AUTOSAR XML (schema 4-2-2)
package /AUTOSAR_EcuM/SwComponentTypes
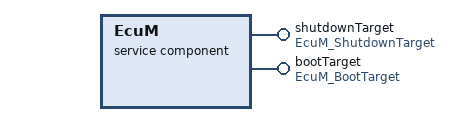
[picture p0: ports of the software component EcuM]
  service sw component type EcuM
    provide port shutdownTarget: provided-interface=EcuM_ShutdownTarget
    provide port bootTarget: provided-interface=EcuM_BootTarget
    behavior IB_EcuM
      7 x operation invoked event:
        OIE_GetShutdownCause: start-on-event=GetShutdownCause, operation=shutdownTarget.GetShutdownCause
        OIE_GetShutdownTarget: start-on-event=GetShutdownTarget, operation=shutdownTarget.GetShutdownTarget
        OIE_GetLastShutdownTarget: start-on-event=GetLastShutdownTarget, operation=shutdownTarget.GetLastShutdownTarget
        OIE_SelectShutdownCause: start-on-event=SelectShutdownCause, operation=shutdownTarget.SelectShutdownCause
        OIE_SelectShutdownTarget: start-on-event=SelectShutdownTarget, operation=shutdownTarget.SelectShutdownTarget
        OIE_SelectBootTarget: start-on-event=SelectBootTarget, operation=bootTarget.SelectBootTarget
        OIE_GetBootTarget: start-on-event=GetBootTarget, operation=bootTarget.GetBootTarget
      7 x runnable, all with can-be-invoked-concurrently=true:
        SelectShutdownTarget: symbol=EcuM_SelectShutdownTarget
        GetShutdownTarget: symbol=EcuM_GetShutdownTarget
        SelectShutdownCause: symbol=EcuM_SelectShutdownCause
        GetShutdownCause: symbol=EcuM_GetShutdownCause
        GetLastShutdownTarget: symbol=EcuM_GetLastShutdownTarget
        SelectBootTarget: symbol=EcuM_SelectBootTarget
        GetBootTarget: symbol=EcuM_GetBootTarget
package /AUTOSAR_EcuM/PortInterfaces
  client server interface EcuM_BootTarget: is-service=true
    operation SelectBootTarget: possible-error=EcuM_BootTarget/E_NOT_OK
      arg target: type=EcuM_BootTargetType, direction=IN
    operation GetBootTarget: possible-error=EcuM_BootTarget/E_NOT_OK
      arg target: type=EcuM_BootTargetType, direction=OUT
    error E_NOT_OK: error-code=1
  client server interface EcuM_ShutdownTarget: is-service=true
    5 x operation, all with possible-error=EcuM_ShutdownTarget/E_NOT_OK:
      GetLastShutdownTarget
        arg shutdownTarget: type=EcuM_ShutdownTargetType, direction=OUT
        arg shutdownMode: type=EcuM_ShutdownModeType, direction=OUT
      SelectShutdownTarget
        arg shutdownTarget: type=EcuM_ShutdownTargetType, direction=IN
        arg shutdownMode: type=EcuM_ShutdownModeType, direction=IN
      GetShutdownTarget
        arg shutdownTarget: type=EcuM_ShutdownTargetType, direction=OUT
        arg shutdownMode: type=EcuM_ShutdownModeType, direction=OUT
      SelectShutdownCause
        arg shutdownCause: type=EcuM_ShutdownCauseType, direction=IN
      GetShutdownCause
        arg shutdownCause: type=EcuM_ShutdownCauseType, direction=OUT
    error E_NOT_OK: error-code=1
package /AUTOSAR_EcuM/ImplementationDataTypes
  6 x impl type, all with category=TYPE_REFERENCE:
    EcuM_ShutdownCauseType: compu {0=ECUM_CAUSE_UNKNOWN, 1=ECUM_CAUSE_ECU_STATE, 2=ECUM_CAUSE_WDGM, 3=ECUM_CAUSE_DCM}, implementation-data-type=uint8
    EcuM_TimeType: implementation-data-type=uint32
    EcuM_BootTargetType: compu {0=ECUM_BOOT_TARGET_APP, 1=ECUM_BOOT_TARGET_OEM_BOOTLOADER, 2=ECUM_BOOT_TARGET_SYS_BOOTLOADER}, implementation-data-type=uint8
    EcuM_ShutdownModeType: compu {0=ECUM_RESET_MCU, 1=ECUM_RESET_WDGM, 2=ECUM_RESET_IO, 3=ECUM_RESET_HARD, 4=ECUM_RESET_KEYOFFON, 5=ECUM_RESET_SOFT, 6=ECUM_RESET_WAKEUP, 7=ECUM_RESET_WDG}, implementation-data-type=uint16
    EcuM_ShutdownTargetType: compu {0=ECUM_SHUTDOWN_TARGET_SLEEP, 1=ECUM_SHUTDOWN_TARGET_RESET, 2=ECUM_SHUTDOWN_TARGET_OFF}, implementation-data-type=uint8
    EcuM_UserType: implementation-data-type=uint16
package /AUTOSAR_EcuM/SwcImplementations
  swc implementation EcuM: programming-language=C, sw-version=4.0.0, behavior=IB_EcuM
    code-descriptors:
      code CodeDescriptor: artifact-descriptors=autosar-engineering-object={short-label=ArEngObj, category=SWSRC}
